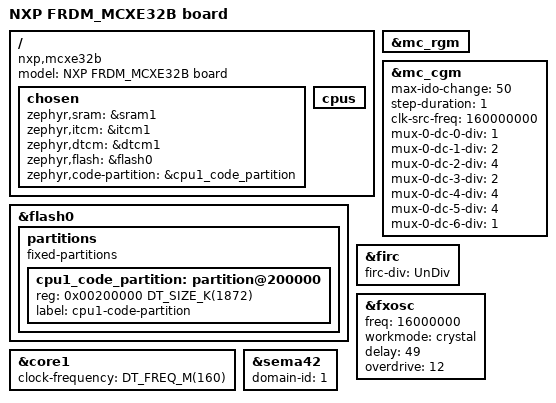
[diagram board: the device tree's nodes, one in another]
/*
 * SPDX-FileCopyrightText: Copyright 2026 NXP
 *
 * SPDX-License-Identifier: Apache-2.0
 */

/dts-v1/;

#include <nxp/mcx/mcxe/nxp_mcxe32b.dtsi>
#include "frdm_mcxe32b-pinctrl.dtsi"

/ {
	compatible = "nxp,mcxe32b";
	model = "NXP FRDM_MCXE32B board";

	chosen {
		zephyr,sram = &sram1;
		zephyr,itcm = &itcm1;
		zephyr,dtcm = &dtcm1;
		zephyr,flash = &flash0;
		zephyr,code-partition = &cpu1_code_partition;
	};
};

/ {
	cpus {
		/delete-node/ cpu@0;
	};
};

&flash0 {
	partitions {
		compatible = "fixed-partitions";
		#address-cells = <1>;
		#size-cells = <1>;

		cpu1_code_partition: partition@200000 {
			/* Offset 0x200000 (2048K) into the 3920K flash node leaves
			 * 1872K, so the partition must not exceed that or it runs
			 * past the end of flash0.
			 */
			reg = <0x00200000 DT_SIZE_K(1872)>;
			label = "cpu1-code-partition";
		};
	};
};

&core1 {
	clock-frequency = <DT_FREQ_M(160)>;
};

&mc_rgm {
	status = "okay";
};

/*
 * CPU0 sets up the clock tree; CPU1 only gates peripheral clocks and
 * reads their rates, see CONFIG_CLOCK_CONTROL_NXP_MC_CGM_INIT.
 */
&mc_cgm {
	max-ido-change = <50>;
	step-duration = <1>;
	clk-src-freq = <160000000>;
	mux-0-dc-0-div = <1>;
	mux-0-dc-1-div = <2>;
	mux-0-dc-2-div = <4>;
	mux-0-dc-3-div = <2>;
	mux-0-dc-4-div = <4>;
	mux-0-dc-5-div = <4>;
	mux-0-dc-6-div = <1>;
	status = "okay";
};

&firc {
	firc-div = "UnDiv";
	status = "okay";
};

&fxosc {
	freq = <16000000>;
	workmode = "crystal";
	delay = <49>;
	overdrive = <12>;
	status = "okay";
};

&sema42 {
	domain-id = <1>;
	status = "okay";
};
